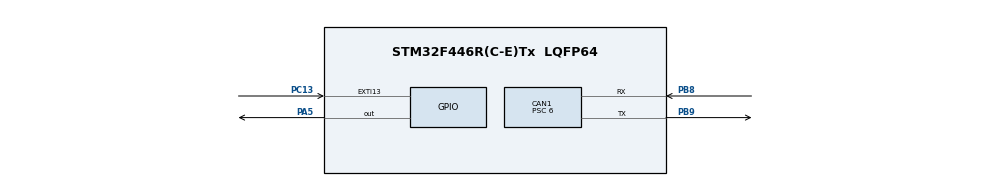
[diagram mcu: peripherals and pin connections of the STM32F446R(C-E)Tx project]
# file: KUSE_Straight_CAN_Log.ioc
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CAN1.BS1=CAN_BS1_11TQ
CAN1.BS2=CAN_BS2_2TQ
CAN1.CalculateBaudRate=500000
CAN1.CalculateTimeBit=2000
CAN1.CalculateTimeQuantum=142.85714285714286
CAN1.Mode=CAN_MODE_NORMAL
CAN1.NART=ENABLE
CAN1.Prescaler=6
Mcu.Family=STM32F4
Mcu.Name=STM32F446R(C-E)Tx
Mcu.Package=LQFP64
NUCLEO-F446RE.BUTTON=1
NUCLEO-F446RE.LD1=true
NVIC.EXTI15_10_IRQn=true\:0\:0\:false\:false\:true\:false\:true\:true
NVIC.PriorityGroup=NVIC_PRIORITYGROUP_0
PA13.GPIO_Label=TMS
PA13.Signal=SYS_JTMS-SWDIO
PA14.GPIO_Label=TCK
PA14.Signal=SYS_JTCK-SWCLK
PA2.GPIO_Label=USART_TX
PA2.Signal=USART2_TX
PA3.GPIO_Label=USART_RX
PA3.Signal=USART2_RX
PA5.Signal=GPIO_Output
PB3.GPIO_Label=SWO
PB3.Signal=SYS_JTDO-SWO
PB8.Mode=CAN_Activate
PB8.Signal=CAN1_RX
PB9.Mode=CAN_Activate
PB9.Signal=CAN1_TX
PC13.Signal=GPXTI13
PC14-OSC32_IN.Signal=RCC_OSC32_IN
PC15-OSC32_OUT.Signal=RCC_OSC32_OUT
PH0-OSC_IN.Signal=RCC_OSC_IN
PH1-OSC_OUT.Signal=RCC_OSC_OUT
ProjectManager.HeapSize=0x200
ProjectManager.StackSize=0x400
ProjectManager.TargetToolchain=STM32CubeIDE
RCC.AHBFreq_Value=84000000
RCC.APB1CLKDivider=RCC_HCLK_DIV2
RCC.APB1Freq_Value=42000000
RCC.APB1TimFreq_Value=84000000
RCC.APB2Freq_Value=84000000
RCC.APB2TimFreq_Value=84000000
RCC.CortexFreq_Value=84000000
RCC.FLatency-AdvancedSettings=FLASH_LATENCY_2
RCC.HCLKFreq_Value=84000000
RCC.HSE_VALUE=8000000
RCC.HSI_VALUE=16000000
RCC.LSE_VALUE=32768
RCC.PLLN=336
RCC.PLLP=RCC_PLLP_DIV4
RCC.SYSCLKFreq_VALUE=84000000
RCC.SYSCLKSource=RCC_SYSCLKSOURCE_PLLCLK
RCC.USBFreq_Value=168000000
RCC.VCOOutputFreq_Value=336000000
USART2.BaudRate=230400
USART2.HardwareFlowControl=UART_HWCONTROL_NONE
USART2.Mode=MODE_TX_RX
USART2.OverSampling=UART_OVERSAMPLING_16
USART2.Parity=UART_PARITY_NONE
USART2.StopBits=UART_STOPBITS_1
USART2.VirtualMode=VM_ASYNC
USART2.WordLength=UART_WORDLENGTH_8B
VP_NUCLEO-F446RE_VS_BSP_COMMON.Mode=COMMON
board=NUCLEO-F446RE

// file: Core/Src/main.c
#include "main.h"
/* USER CODE BEGIN Includes */
#include "app_main.h"
/* USER CODE END Includes */

CAN_HandleTypeDef hcan1;
UART_HandleTypeDef huart2;

static void SystemClock_Config(void);
static void MX_GPIO_Init(void);
static void MX_CAN1_Init(void);
static void MX_USART2_UART_Init(void);

int main(void)
{
  HAL_Init();
  SystemClock_Config();
  MX_GPIO_Init();
  MX_CAN1_Init();
  MX_USART2_UART_Init();
  /* USER CODE BEGIN 2 */
  app_main_run(&hcan1, &huart2);
  /* USER CODE END 2 */
  while (1) { }
}

static void SystemClock_Config(void)
{
  RCC_OscInitTypeDef osc = {0};
  RCC_ClkInitTypeDef clk = {0};
  __HAL_RCC_PWR_CLK_ENABLE();
  __HAL_PWR_VOLTAGESCALING_CONFIG(PWR_REGULATOR_VOLTAGE_SCALE3);
  osc.OscillatorType = RCC_OSCILLATORTYPE_HSI;
  osc.HSIState = RCC_HSI_ON;
  osc.HSICalibrationValue = RCC_HSICALIBRATION_DEFAULT;
  osc.PLL.PLLState = RCC_PLL_ON;
  osc.PLL.PLLSource = RCC_PLLSOURCE_HSI;
  osc.PLL.PLLM = 16;
  osc.PLL.PLLN = 336;
  osc.PLL.PLLP = RCC_PLLP_DIV4;
  osc.PLL.PLLQ = 2;
  if (HAL_RCC_OscConfig(&osc) != HAL_OK) Error_Handler();
  clk.ClockType = RCC_CLOCKTYPE_HCLK | RCC_CLOCKTYPE_SYSCLK |
                  RCC_CLOCKTYPE_PCLK1 | RCC_CLOCKTYPE_PCLK2;
  clk.SYSCLKSource = RCC_SYSCLKSOURCE_PLLCLK;
  clk.AHBCLKDivider = RCC_SYSCLK_DIV1;
  clk.APB1CLKDivider = RCC_HCLK_DIV2;
  clk.APB2CLKDivider = RCC_HCLK_DIV1;
  if (HAL_RCC_ClockConfig(&clk, FLASH_LATENCY_2) != HAL_OK) Error_Handler();
}

static void MX_CAN1_Init(void)
{
  hcan1.Instance = CAN1;
  hcan1.Init.Prescaler = 6;
  hcan1.Init.Mode = CAN_MODE_NORMAL;
  hcan1.Init.SyncJumpWidth = CAN_SJW_1TQ;
  hcan1.Init.TimeSeg1 = CAN_BS1_11TQ;
  hcan1.Init.TimeSeg2 = CAN_BS2_2TQ;
  hcan1.Init.TimeTriggeredMode = DISABLE;
  hcan1.Init.AutoBusOff = ENABLE;
  hcan1.Init.AutoWakeUp = DISABLE;
  hcan1.Init.AutoRetransmission = ENABLE;
  hcan1.Init.ReceiveFifoLocked = DISABLE;
  hcan1.Init.TransmitFifoPriority = DISABLE;
  if (HAL_CAN_Init(&hcan1) != HAL_OK) Error_Handler();
}

static void MX_GPIO_Init(void)
{
  __HAL_RCC_GPIOC_CLK_ENABLE();
  __HAL_RCC_GPIOH_CLK_ENABLE();
  __HAL_RCC_GPIOA_CLK_ENABLE();
  __HAL_RCC_GPIOB_CLK_ENABLE();
}

static void MX_USART2_UART_Init(void)
{
  huart2.Instance = USART2;
  huart2.Init.BaudRate = 230400;
  huart2.Init.WordLength = UART_WORDLENGTH_8B;
  huart2.Init.StopBits = UART_STOPBITS_1;
  huart2.Init.Parity = UART_PARITY_NONE;
  huart2.Init.Mode = UART_MODE_TX_RX;
  huart2.Init.HwFlowCtl = UART_HWCONTROL_NONE;
  huart2.Init.OverSampling = UART_OVERSAMPLING_16;
  if (HAL_UART_Init(&huart2) != HAL_OK) Error_Handler();
}

void Error_Handler(void)
{
  __disable_irq();
  while (1) { }
}
